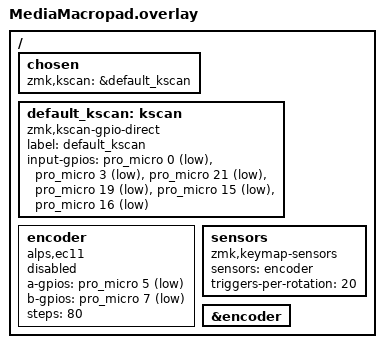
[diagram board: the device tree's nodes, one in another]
/ {
	chosen {
		zmk,kscan = &default_kscan;		
	};

	default_kscan: kscan {
		compatible = "zmk,kscan-gpio-direct";
		label = "default_kscan";
		
		input-gpios =
			<&pro_micro 0 (GPIO_ACTIVE_LOW | GPIO_PULL_UP)>,
			<&pro_micro 3 (GPIO_ACTIVE_LOW | GPIO_PULL_UP)>,
			<&pro_micro 21 (GPIO_ACTIVE_LOW | GPIO_PULL_UP)>,
			<&pro_micro 19 (GPIO_ACTIVE_LOW | GPIO_PULL_UP)>,
			<&pro_micro 15 (GPIO_ACTIVE_LOW | GPIO_PULL_UP)>,
			<&pro_micro 16 (GPIO_ACTIVE_LOW | GPIO_PULL_UP)>;
	};
	
	encoder: encoder {
		compatible = "alps,ec11";
		a-gpios = <&pro_micro 5 (GPIO_ACTIVE_LOW | GPIO_PULL_UP)>;
		b-gpios = <&pro_micro 7 (GPIO_ACTIVE_LOW | GPIO_PULL_UP)>;
		steps = <80>;
		status = "disabled";
	};
	
	sensors: sensors {
		compatible = "zmk,keymap-sensors";
		sensors = <&encoder>;
		triggers-per-rotation = <20>;
	};
	
	&encoder {
		status = "okay";
	};
};
